# XHSC_HC32A052 register map
Vendor: XHSC Co.Ltd; Series: ARMCM4; File version: 1.2
CPU: CM0 r0p0, little endian, no MPU, no FPU, 3 interrupt priority bits
Registers are 32-bit, read-write, reset 0x0 unless marked. A register's access mark holds for its fields unless they carry their own. Offsets are from the block's base; [hi:lo] are bit positions; {n}, {i} and the like mark numbered series; 'fields as' and 'values as' point back to an identical list.

## I2CSLV
Base 0x40004C00
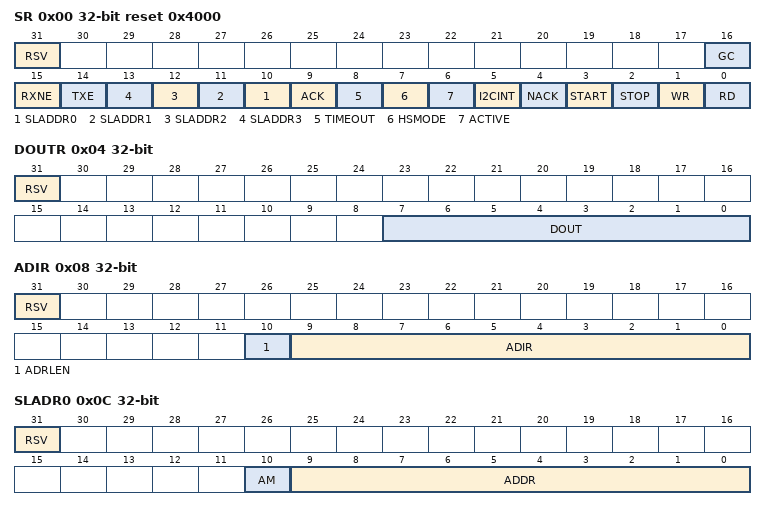
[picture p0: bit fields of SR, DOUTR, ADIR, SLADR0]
0x00 SR ro reset 0x4000 (reset mask 0x1FFFF)
  [31] RSV, [16] GC, [15] RXNE, [14] TXE, [n+10] SLADDR{n} (n=0..3), [9] ACK, [8] TIMEOUT, [7] HSMODE, [6] ACTIVE, [5] I2CINT, [4] NACK, [3] START, [2] STOP, [1] WR, [0] RD
0x04 DOUTR (reset mask 0xFF)
  [31] RSV, [7:0] DOUT
0x08 ADIR ro (reset mask 0x7FFF)
  [31] RSV, [10] ADRLEN, [9:0] ADIR
0x0C SLADR0 (reset mask 0x7FFF)
  [31] RSV, [10] AM, [9:0] ADDR
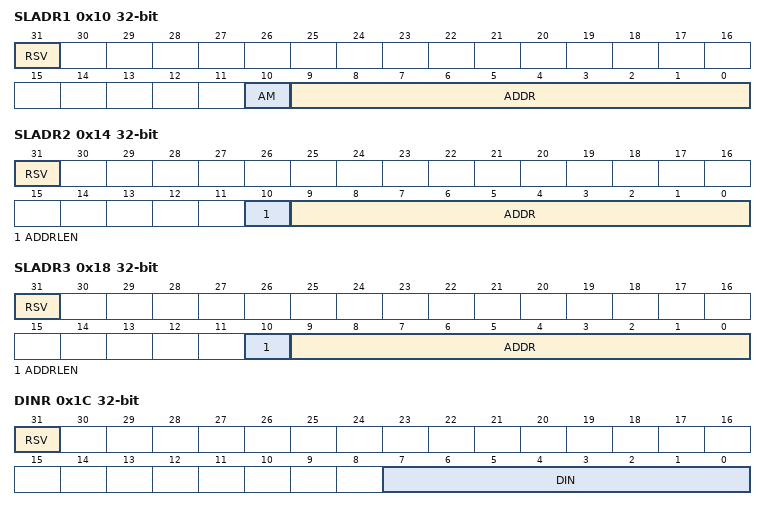
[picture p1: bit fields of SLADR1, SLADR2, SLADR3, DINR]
0x10 SLADR1 (reset mask 0x7FFF)
  [31] RSV, [10] AM, [9:0] ADDR
0x14 SLADR2 (reset mask 0x7FFF)
  [31] RSV, [10] ADDRLEN, [9:0] ADDR
0x18 SLADR3 (reset mask 0x7FFF)
  [31] RSV, [10] ADDRLEN, [9:0] ADDR
0x1C DINR ro (reset mask 0xFF)
  [31] RSV, [7:0] DIN
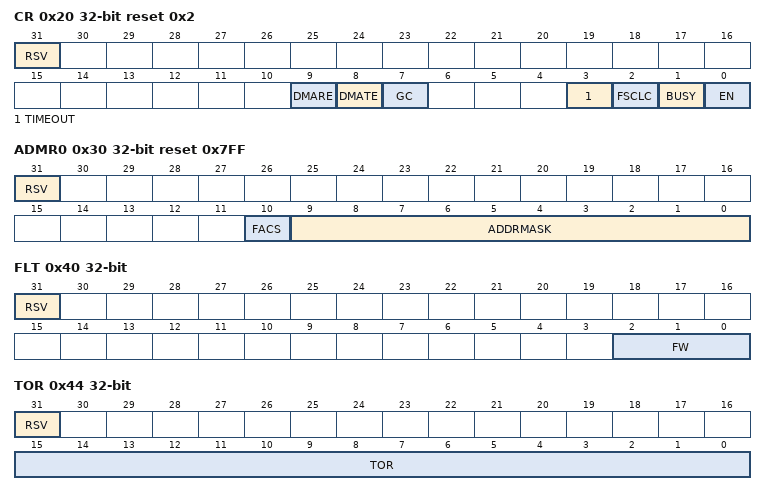
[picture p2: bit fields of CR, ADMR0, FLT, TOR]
0x20 CR reset 0x2 (reset mask 0x38F)
  [31] RSV, [9] DMARE, [8] DMATE, [7] GC, [3] TIMEOUT, [2] FSCLC, [1] BUSY, [0] EN
0x30 ADMR0 reset 0x7FF (reset mask 0xFFFF)
  [31] RSV, [10] FACS, [9:0] ADDRMASK
0x40 FLT (reset mask 0x7)
  [31] RSV, [2:0] FW
0x44 TOR (reset mask 0xFFFF)
  [31] RSV, [15:0] TOR
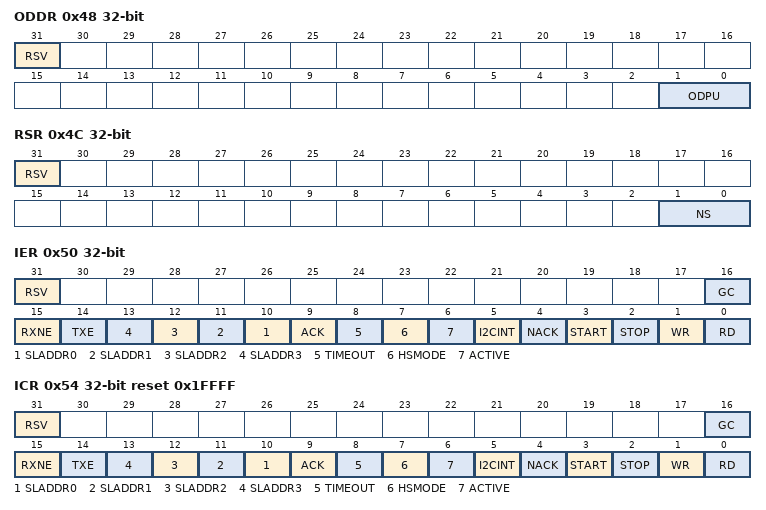
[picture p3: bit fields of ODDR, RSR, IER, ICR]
0x48 ODDR (reset mask 0x3)
  [31] RSV, [1:0] ODPU
0x4C RSR (reset mask 0x3)
  [31] RSV, [1:0] NS
0x50 IER (reset mask 0x1FFFF)
  fields as SR
0x54 ICR wo reset 0x1FFFF (reset mask 0x1FFFF)
  fields as SR
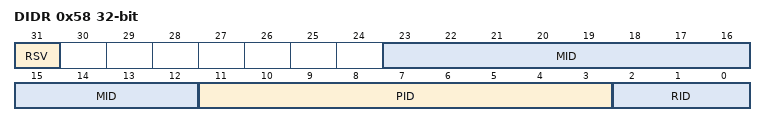
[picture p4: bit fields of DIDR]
0x58 DIDR (reset mask 0xFFFFFF)
  [31] RSV, [23:12] MID, [11:3] PID, [2:0] RID

## IWDT
Base 0x40001080
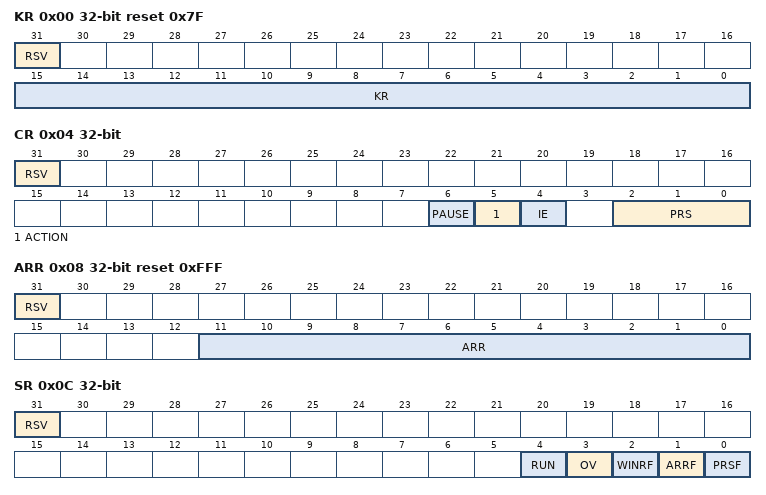
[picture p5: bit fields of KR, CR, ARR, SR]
0x00 KR wo reset 0x7F (reset mask 0xFFFF)
  [31] RSV, [15:0] KR
0x04 CR (reset mask 0x77)
  [31] RSV, [6] PAUSE, [5] ACTION, [4] IE, [2:0] PRS
0x08 ARR reset 0xFFF (reset mask 0xFFF)
  [31] RSV, [11:0] ARR
0x0C SR (reset mask 0x1F)
  [31] RSV ro, [4] RUN ro, [3] OV, [2] WINRF ro, [1] ARRF ro, [0] PRSF ro
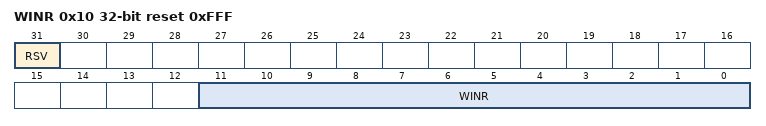
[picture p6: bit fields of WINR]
0x10 WINR reset 0xFFF (reset mask 0xFFF)
  [31] RSV, [11:0] WINR

## LPTIM
Base 0x40000C00
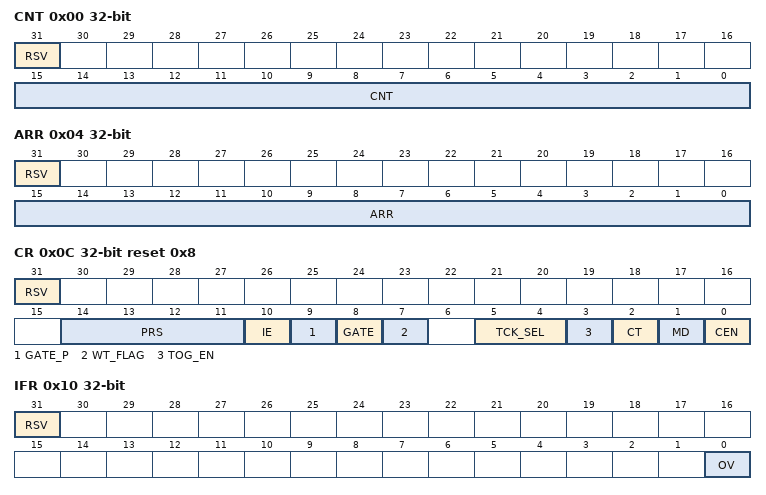
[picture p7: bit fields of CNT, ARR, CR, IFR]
0x00 CNT ro (reset mask 0xFFFF)
  [31] RSV, [15:0] CNT
0x04 ARR (reset mask 0xFFFF)
  [31] RSV, [15:0] ARR
0x0C CR reset 0x8 (reset mask 0x7FBF)
  [31] RSV, [14:11] PRS, [10] IE, [9] GATE_P, [8] GATE, [7] WT_FLAG ro, [5:4] TCK_SEL, [3] TOG_EN, [2] CT, [1] MD, [0] CEN
0x10 IFR ro (reset mask 0x1)
  [31] RSV rw, [0] OV
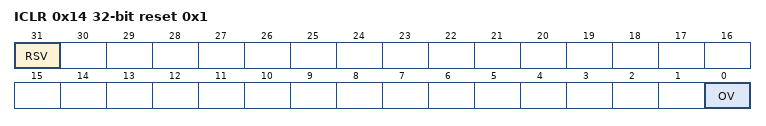
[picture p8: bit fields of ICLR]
0x14 ICLR reset 0x1 (reset mask 0x1)
  [31] RSV, [0] OV wo

## LPUART0 — desc LPUART
Base 0x40000000
Same registers: LPUART1 0x40004000
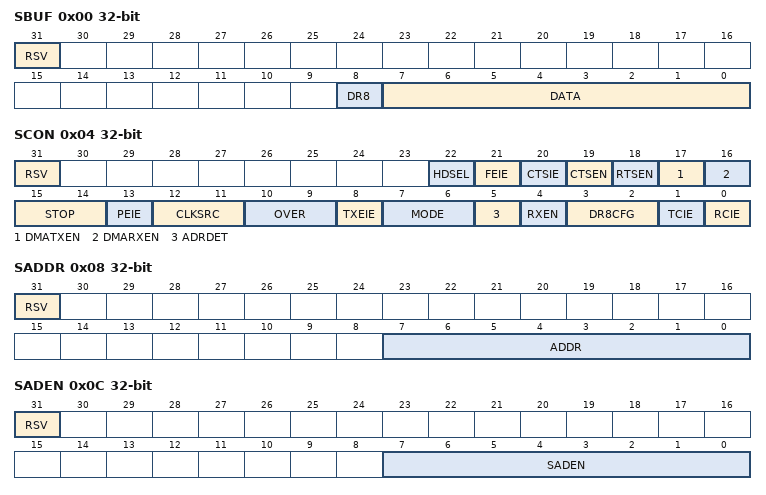
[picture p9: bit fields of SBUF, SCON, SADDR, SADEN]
0x00 SBUF (reset mask 0x1FF)
  [31] RSV, [8] DR8, [7:0] DATA
0x04 SCON (reset mask 0x7FFFFF)
  [31] RSV, [22] HDSEL, [21] FEIE, [20] CTSIE, [19] CTSEN, [18] RTSEN, [17] DMATXEN, [16] DMARXEN, [15:14] STOP, [13] PEIE, [12:11] CLKSRC, [10:9] OVER, [8] TXEIE, [7:6] MODE, [5] ADRDET, [4] RXEN, [3:2] DR8CFG, [1] TCIE, [0] RCIE
0x08 SADDR (reset mask 0xFF)
  [31] RSV, [7:0] ADDR
0x0C SADEN (reset mask 0xFF)
  [31] RSV, [7:0] SADEN
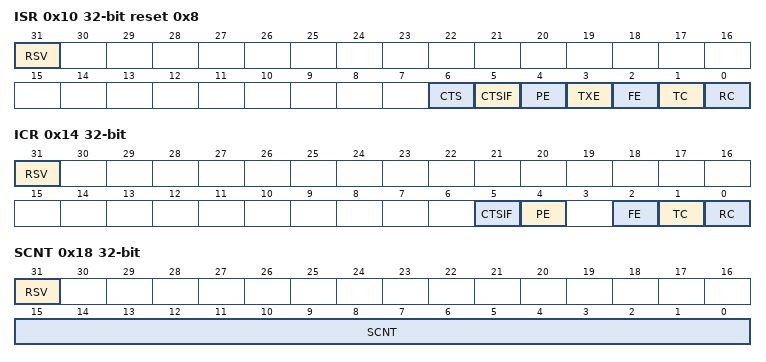
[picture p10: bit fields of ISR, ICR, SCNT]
0x10 ISR ro reset 0x8 (reset mask 0x7F)
  [31] RSV, [6] CTS, [5] CTSIF, [4] PE, [3] TXE, [2] FE, [1] TC, [0] RC
0x14 ICR (reset mask 0x37)
  [31] RSV, [5] CTSIF, [4] PE, [2] FE, [1] TC, [0] RC
0x18 SCNT (reset mask 0xFFFF)
  [31] RSV, [15:0] SCNT

## LVD
Base 0x40002480
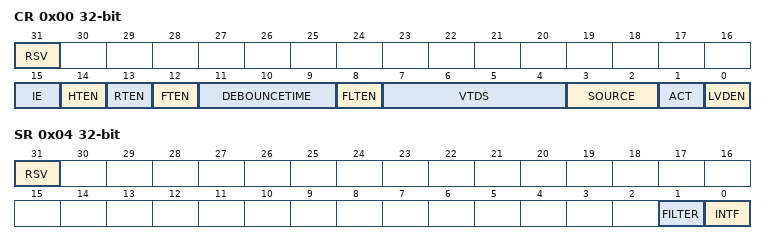
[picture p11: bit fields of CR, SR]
0x00 CR (reset mask 0xFFFF)
  [31] RSV, [15] IE, [14] HTEN, [13] RTEN, [12] FTEN, [11:9] DEBOUNCETIME, [8] FLTEN, [7:4] VTDS, [3:2] SOURCE, [1] ACT, [0] LVDEN
0x04 SR (reset mask 0xFFFF)
  [31] RSV, [1] FILTER ro, [0] INTF

## OPA
Base 0x40002600
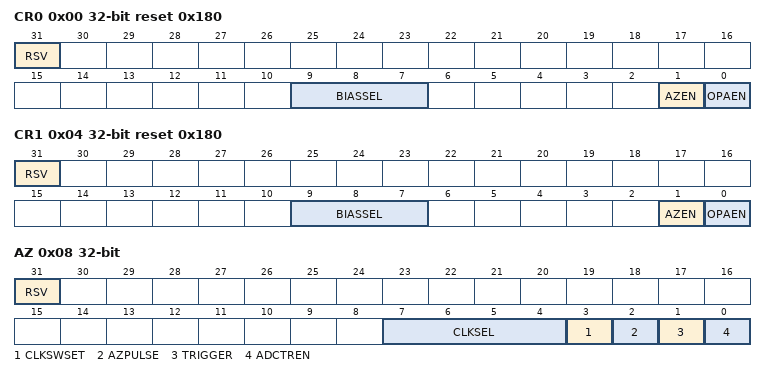
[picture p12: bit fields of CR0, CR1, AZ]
0x00 CR0 reset 0x180 (reset mask 0x383)
  [31] RSV, [9:7] BIASSEL, [1] AZEN, [0] OPAEN
0x04 CR1 reset 0x180 (reset mask 0x383)
  [31] RSV, [9:7] BIASSEL, [1] AZEN, [0] OPAEN
0x08 AZ (reset mask 0xFF)
  [31] RSV, [7:4] CLKSEL, [3] CLKSWSET, [2] AZPULSE, [1] TRIGGER wo, [0] ADCTREN

## RAM
Base 0x40020400
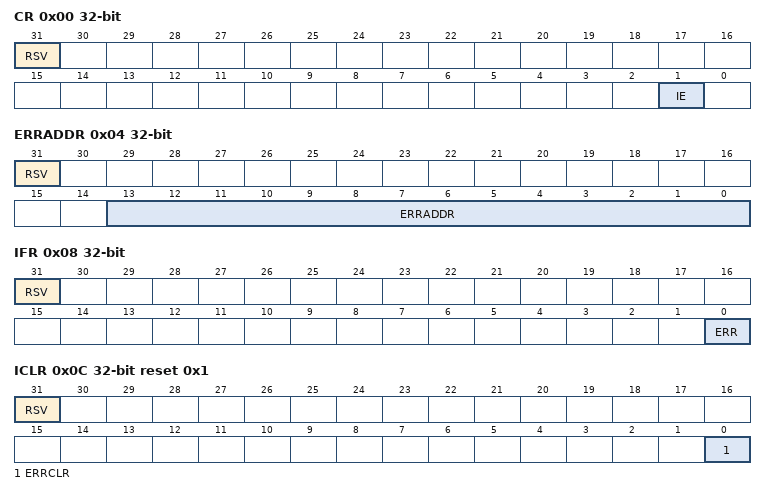
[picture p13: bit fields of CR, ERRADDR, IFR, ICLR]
0x00 CR (reset mask 0x2)
  [31] RSV, [1] IE
0x04 ERRADDR ro (reset mask 0x3FFF)
  [31] RSV, [13:0] ERRADDR
0x08 IFR ro (reset mask 0x1)
  [31] RSV, [0] ERR
0x0C ICLR reset 0x1 (reset mask 0x1)
  [31] RSV, [0] ERRCLR
